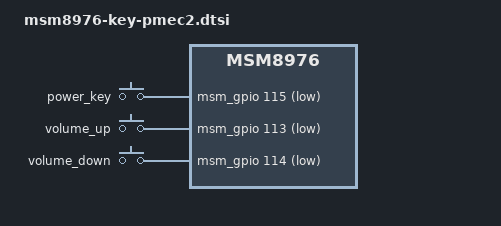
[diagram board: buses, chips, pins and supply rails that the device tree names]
&soc
{
	gpio_keys {
		compatible = "gpio-keys";
		input-name = "gpio-keys";
		pinctrl-names = "tlmm_gpio_key_active","tlmm_gpio_key_suspend";
		pinctrl-0 = <&gpio_key_active>;
		pinctrl-1 = <&gpio_key_suspend>;

		power_key {
			label = "power_key";
			gpios = <&msm_gpio 115 0x1>;
			linux,input-type = <1>;
			linux,code = <116>;
			gpio-key,wakeup;
			debounce-interval = <20>;
		};

		vol_up {
			label = "volume_up";
			gpios = <&msm_gpio 113 0x1>;
			linux,input-type = <1>;
			linux,code = <115>;
			debounce-interval = <20>;
		};

		vol_down {
			label = "volume_down";
			gpios = <&msm_gpio 114 0x1>;
			linux,input-type = <1>;
			linux,code = <114>;
			debounce-interval = <20>;
		};
	};

	keyled {
		compatible	= "keyled";
		key_down_delay	= <3000>;
		keys_down	= <116 114 0>;
	};
};
